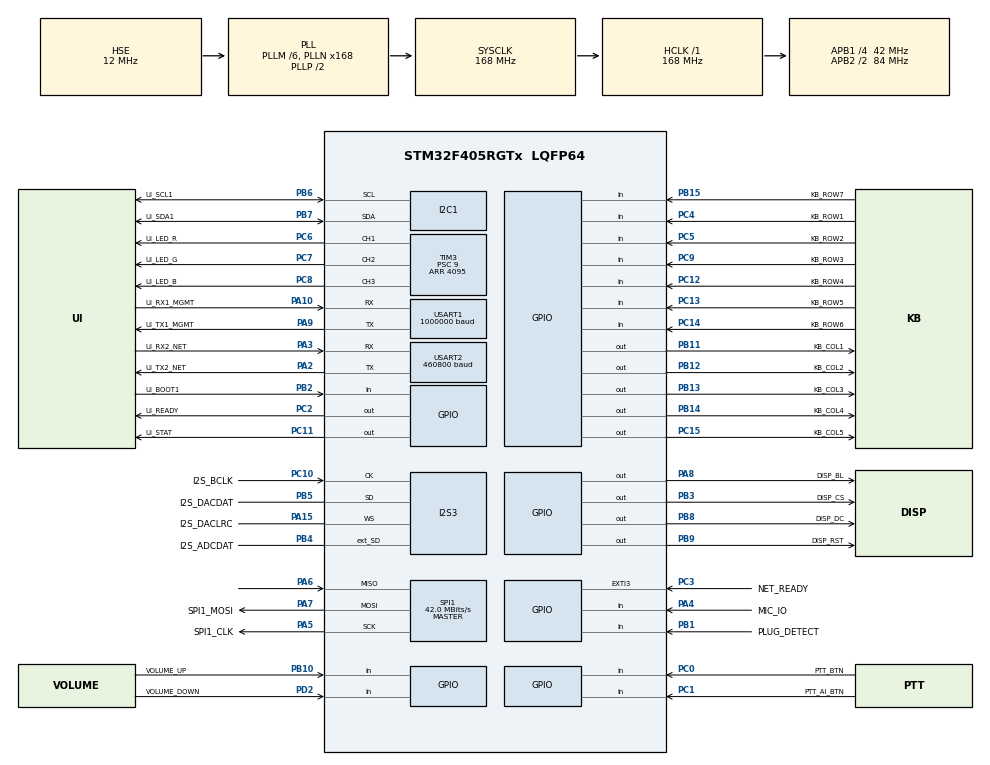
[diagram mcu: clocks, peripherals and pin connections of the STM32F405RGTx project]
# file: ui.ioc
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Dma.I2S3_EXT_RX.5.Direction=DMA_PERIPH_TO_MEMORY
Dma.I2S3_EXT_RX.5.FIFOMode=DMA_FIFOMODE_DISABLE
Dma.I2S3_EXT_RX.5.Instance=DMA1_Stream0
Dma.I2S3_EXT_RX.5.MemDataAlignment=DMA_MDATAALIGN_HALFWORD
Dma.I2S3_EXT_RX.5.MemInc=DMA_MINC_ENABLE
Dma.I2S3_EXT_RX.5.Mode=DMA_CIRCULAR
Dma.I2S3_EXT_RX.5.PeriphDataAlignment=DMA_PDATAALIGN_HALFWORD
Dma.I2S3_EXT_RX.5.PeriphInc=DMA_PINC_DISABLE
Dma.I2S3_EXT_RX.5.Priority=DMA_PRIORITY_HIGH
Dma.Request0=USART2_RX
Dma.Request1=USART2_TX
Dma.Request2=USART1_RX
Dma.Request3=USART1_TX
Dma.Request4=SPI3_TX
Dma.Request5=I2S3_EXT_RX
Dma.Request6=SPI1_RX
Dma.Request7=SPI1_TX
Dma.SPI1_RX.6.Direction=DMA_PERIPH_TO_MEMORY
Dma.SPI1_RX.6.FIFOMode=DMA_FIFOMODE_DISABLE
Dma.SPI1_RX.6.Instance=DMA2_Stream0
Dma.SPI1_RX.6.MemDataAlignment=DMA_MDATAALIGN_BYTE
Dma.SPI1_RX.6.MemInc=DMA_MINC_ENABLE
Dma.SPI1_RX.6.Mode=DMA_NORMAL
Dma.SPI1_RX.6.PeriphDataAlignment=DMA_PDATAALIGN_BYTE
Dma.SPI1_RX.6.PeriphInc=DMA_PINC_DISABLE
Dma.SPI1_RX.6.Priority=DMA_PRIORITY_LOW
Dma.SPI1_TX.7.Direction=DMA_MEMORY_TO_PERIPH
Dma.SPI1_TX.7.FIFOMode=DMA_FIFOMODE_DISABLE
Dma.SPI1_TX.7.Instance=DMA2_Stream3
Dma.SPI1_TX.7.MemDataAlignment=DMA_MDATAALIGN_BYTE
Dma.SPI1_TX.7.MemInc=DMA_MINC_ENABLE
Dma.SPI1_TX.7.Mode=DMA_NORMAL
Dma.SPI1_TX.7.PeriphDataAlignment=DMA_PDATAALIGN_BYTE
Dma.SPI1_TX.7.PeriphInc=DMA_PINC_DISABLE
Dma.SPI1_TX.7.Priority=DMA_PRIORITY_LOW
Dma.SPI3_TX.4.Direction=DMA_MEMORY_TO_PERIPH
Dma.SPI3_TX.4.FIFOMode=DMA_FIFOMODE_DISABLE
Dma.SPI3_TX.4.Instance=DMA1_Stream7
Dma.SPI3_TX.4.MemDataAlignment=DMA_MDATAALIGN_HALFWORD
Dma.SPI3_TX.4.MemInc=DMA_MINC_ENABLE
Dma.SPI3_TX.4.Mode=DMA_CIRCULAR
Dma.SPI3_TX.4.PeriphDataAlignment=DMA_PDATAALIGN_HALFWORD
Dma.SPI3_TX.4.PeriphInc=DMA_PINC_DISABLE
Dma.SPI3_TX.4.Priority=DMA_PRIORITY_HIGH
Dma.USART1_RX.2.Direction=DMA_PERIPH_TO_MEMORY
Dma.USART1_RX.2.FIFOMode=DMA_FIFOMODE_DISABLE
Dma.USART1_RX.2.Instance=DMA2_Stream5
Dma.USART1_RX.2.MemDataAlignment=DMA_MDATAALIGN_BYTE
Dma.USART1_RX.2.MemInc=DMA_MINC_ENABLE
Dma.USART1_RX.2.Mode=DMA_CIRCULAR
Dma.USART1_RX.2.PeriphDataAlignment=DMA_PDATAALIGN_BYTE
Dma.USART1_RX.2.PeriphInc=DMA_PINC_DISABLE
Dma.USART1_RX.2.Priority=DMA_PRIORITY_LOW
Dma.USART1_TX.3.Direction=DMA_MEMORY_TO_PERIPH
Dma.USART1_TX.3.FIFOMode=DMA_FIFOMODE_DISABLE
Dma.USART1_TX.3.Instance=DMA2_Stream7
Dma.USART1_TX.3.MemDataAlignment=DMA_MDATAALIGN_BYTE
Dma.USART1_TX.3.MemInc=DMA_MINC_ENABLE
Dma.USART1_TX.3.Mode=DMA_NORMAL
Dma.USART1_TX.3.PeriphDataAlignment=DMA_PDATAALIGN_BYTE
Dma.USART1_TX.3.PeriphInc=DMA_PINC_DISABLE
Dma.USART1_TX.3.Priority=DMA_PRIORITY_LOW
Dma.USART2_RX.0.Direction=DMA_PERIPH_TO_MEMORY
Dma.USART2_RX.0.FIFOMode=DMA_FIFOMODE_DISABLE
Dma.USART2_RX.0.Instance=DMA1_Stream5
Dma.USART2_RX.0.MemDataAlignment=DMA_MDATAALIGN_BYTE
Dma.USART2_RX.0.MemInc=DMA_MINC_ENABLE
Dma.USART2_RX.0.Mode=DMA_CIRCULAR
Dma.USART2_RX.0.PeriphDataAlignment=DMA_PDATAALIGN_BYTE
Dma.USART2_RX.0.PeriphInc=DMA_PINC_DISABLE
Dma.USART2_RX.0.Priority=DMA_PRIORITY_VERY_HIGH
Dma.USART2_TX.1.Direction=DMA_MEMORY_TO_PERIPH
Dma.USART2_TX.1.FIFOMode=DMA_FIFOMODE_DISABLE
Dma.USART2_TX.1.Instance=DMA1_Stream6
Dma.USART2_TX.1.MemDataAlignment=DMA_MDATAALIGN_BYTE
Dma.USART2_TX.1.MemInc=DMA_MINC_ENABLE
Dma.USART2_TX.1.Mode=DMA_NORMAL
Dma.USART2_TX.1.PeriphDataAlignment=DMA_PDATAALIGN_BYTE
Dma.USART2_TX.1.PeriphInc=DMA_PINC_DISABLE
Dma.USART2_TX.1.Priority=DMA_PRIORITY_VERY_HIGH
I2S3.AudioFreq=I2S_AUDIOFREQ_8K
I2S3.CPOL=I2S_CPOL_LOW
I2S3.DataFormat=I2S_DATAFORMAT_16B_EXTENDED
I2S3.ErrorAudioFreq=-0.36 %
I2S3.FullDuplexMode=I2S_FULLDUPLEXMODE_ENABLE
I2S3.Instance=SPI$Index
I2S3.RealAudioFreq=7.971 KHz
I2S3.Standard=I2S_STANDARD_MSB
I2S3.VirtualMode=I2S_MODE_SLAVE
Mcu.Family=STM32F4
Mcu.Name=STM32F405RGTx
Mcu.Package=LQFP64
NVIC.DMA1_Stream0_IRQn=true\:0\:0\:false\:false\:true\:false\:true\:true
NVIC.DMA1_Stream5_IRQn=true\:1\:0\:true\:false\:true\:false\:true\:true
NVIC.DMA1_Stream6_IRQn=true\:1\:0\:true\:false\:true\:false\:true\:true
NVIC.DMA1_Stream7_IRQn=true\:0\:0\:false\:false\:true\:false\:true\:true
NVIC.DMA2_Stream0_IRQn=true\:0\:0\:false\:false\:true\:false\:true\:true
NVIC.DMA2_Stream3_IRQn=true\:2\:0\:false\:false\:true\:false\:true\:true
NVIC.DMA2_Stream5_IRQn=true\:1\:0\:true\:false\:true\:false\:true\:true
NVIC.DMA2_Stream7_IRQn=true\:1\:0\:true\:false\:true\:false\:true\:true
NVIC.PriorityGroup=NVIC_PRIORITYGROUP_4
NVIC.RCC_IRQn=true\:0\:0\:false\:false\:true\:true\:false\:true
NVIC.SPI1_IRQn=true\:0\:0\:false\:false\:true\:true\:true\:true
NVIC.SPI3_IRQn=true\:0\:0\:false\:false\:true\:true\:true\:true
NVIC.TIM2_IRQn=true\:0\:0\:false\:false\:true\:true\:true\:true
NVIC.TIM3_IRQn=true\:0\:0\:false\:false\:true\:true\:true\:true
NVIC.TIM4_IRQn=true\:0\:0\:false\:false\:true\:true\:true\:true
NVIC.TIM5_IRQn=true\:0\:0\:false\:false\:true\:true\:true\:true
NVIC.TIM6_DAC_IRQn=true\:0\:0\:false\:false\:true\:true\:true\:true
NVIC.USART1_IRQn=true\:0\:0\:false\:false\:true\:true\:true\:true
NVIC.USART2_IRQn=true\:0\:0\:false\:false\:true\:true\:true\:true
PA10.GPIO_Label=UI_RX1_MGMT
PA10.Mode=Asynchronous
PA10.Signal=USART1_RX
PA13.Mode=Serial_Wire
PA13.Signal=SYS_JTMS-SWDIO
PA14.Mode=Serial_Wire
PA14.Signal=SYS_JTCK-SWCLK
PA15.GPIO_Label=I2S_DACLRC
PA15.Mode=Full_Duplex_Slave
PA15.Signal=I2S3_WS
PA2.GPIO_Label=UI_TX2_NET
PA2.Mode=Asynchronous
PA2.Signal=USART2_TX
PA3.GPIO_Label=UI_RX2_NET
PA3.GPIO_PuPd=GPIO_PULLDOWN
PA3.Mode=Asynchronous
PA3.Signal=USART2_RX
PA4.GPIO_Label=MIC_IO
PA4.Signal=GPIO_Input
PA5.GPIO_Label=SPI1_CLK
PA5.Mode=Full_Duplex_Master
PA5.Signal=SPI1_SCK
PA6.Mode=Full_Duplex_Master
PA6.Signal=SPI1_MISO
PA7.GPIO_Label=SPI1_MOSI
PA7.Mode=Full_Duplex_Master
PA7.Signal=SPI1_MOSI
PA8.GPIO_Label=DISP_BL
PA8.GPIO_PuPd=GPIO_NOPULL
PA8.Signal=GPIO_Output
PA9.GPIO_Label=UI_TX1_MGMT
PA9.Mode=Asynchronous
PA9.Signal=USART1_TX
PB1.GPIO_Label=PLUG_DETECT
PB1.Signal=GPIO_Input
PB10.GPIO_Label=VOLUME_UP
PB10.Signal=GPIO_Input
PB11.GPIO_Label=KB_COL1
PB11.Signal=GPIO_Output
PB12.GPIO_Label=KB_COL2
PB12.Signal=GPIO_Output
PB13.GPIO_Label=KB_COL3
PB13.Signal=GPIO_Output
PB14.GPIO_Label=KB_COL4
PB14.Signal=GPIO_Output
PB15.GPIO_Label=KB_ROW7
PB15.GPIO_PuPd=GPIO_PULLDOWN
PB15.Signal=GPIO_Input
PB2.GPIO_Label=UI_BOOT1
PB2.Signal=GPIO_Input
PB3.GPIO_Label=DISP_CS
PB3.Signal=GPIO_Output
PB4.GPIO_Label=I2S_ADCDAT
PB4.Mode=Full_Duplex_Slave
PB4.Signal=I2S3_ext_SD
PB5.GPIO_Label=I2S_DACDAT
PB5.Mode=Full_Duplex_Slave
PB5.Signal=I2S3_SD
PB6.GPIO_Label=UI_SCL1
PB6.Mode=I2C
PB6.Signal=I2C1_SCL
PB7.GPIO_Label=UI_SDA1
PB7.Mode=I2C
PB7.Signal=I2C1_SDA
PB8.GPIO_Label=DISP_DC
PB8.Signal=GPIO_Output
PB9.GPIO_Label=DISP_RST
PB9.Signal=GPIO_Output
PC0.GPIO_Label=PTT_BTN
PC0.GPIO_PuPd=GPIO_PULLUP
PC0.Signal=GPIO_Input
PC1.GPIO_Label=PTT_AI_BTN
PC1.GPIO_PuPd=GPIO_PULLUP
PC1.Signal=GPIO_Input
PC10.GPIO_Label=I2S_BCLK
PC10.Mode=Full_Duplex_Slave
PC10.Signal=I2S3_CK
PC11.GPIO_Label=UI_STAT
PC11.GPIO_PuPd=GPIO_PULLDOWN
PC11.GPIO_Speed=GPIO_SPEED_FREQ_MEDIUM
PC11.Signal=GPIO_Output
PC12.GPIO_Label=KB_ROW4
PC12.GPIO_PuPd=GPIO_PULLDOWN
PC12.Signal=GPIO_Input
PC13-ANTI_TAMP.GPIO_Label=KB_ROW5
PC13-ANTI_TAMP.GPIO_PuPd=GPIO_PULLDOWN
PC13-ANTI_TAMP.Signal=GPIO_Input
PC14-OSC32_IN.GPIO_Label=KB_ROW6
PC14-OSC32_IN.GPIO_PuPd=GPIO_PULLDOWN
PC14-OSC32_IN.Signal=GPIO_Input
PC15-OSC32_OUT.GPIO_Label=KB_COL5
PC15-OSC32_OUT.Signal=GPIO_Output
PC2.GPIO_Label=UI_READY
PC2.Signal=GPIO_Output
PC3.GPIO_Label=NET_READY
PC3.Signal=GPXTI3
PC4.GPIO_Label=KB_ROW1
PC4.GPIO_PuPd=GPIO_PULLDOWN
PC4.Signal=GPIO_Input
PC5.GPIO_Label=KB_ROW2
PC5.GPIO_PuPd=GPIO_PULLDOWN
PC5.Signal=GPIO_Input
PC6.GPIO_Label=UI_LED_R
PC6.Signal=S_TIM3_CH1
PC7.GPIO_Label=UI_LED_G
PC7.Signal=S_TIM3_CH2
PC8.GPIO_Label=UI_LED_B
PC8.Signal=S_TIM3_CH3
PC9.GPIO_Label=KB_ROW3
PC9.GPIO_PuPd=GPIO_PULLDOWN
PC9.Signal=GPIO_Input
PD2.GPIO_Label=VOLUME_DOWN
PD2.Signal=GPIO_Input
PH0-OSC_IN.GPIO_Label=MCLK
PH0-OSC_IN.Mode=HSE-External-Clock-Source
PH0-OSC_IN.Signal=RCC_OSC_IN
PH1-OSC_OUT.GPIO_Label=NC
PH1-OSC_OUT.Mode=HSE-External-Clock-Source
PH1-OSC_OUT.Signal=RCC_OSC_OUT
ProjectManager.HeapSize=0x200
ProjectManager.StackSize=0x400
ProjectManager.TargetToolchain=CMake
RCC.48MHZClocksFreq_Value=48000000
RCC.AHBFreq_Value=168000000
RCC.APB1CLKDivider=RCC_HCLK_DIV4
RCC.APB1Freq_Value=42000000
RCC.APB1TimFreq_Value=84000000
RCC.APB2CLKDivider=RCC_HCLK_DIV2
RCC.APB2Freq_Value=84000000
RCC.APB2TimFreq_Value=168000000
RCC.CortexFreq_Value=168000000
RCC.EXTERNAL_CLOCK_VALUE=2048000
RCC.HCLKFreq_Value=168000000
RCC.HSE_VALUE=12000000
RCC.HSI_VALUE=16000000
RCC.LSE_VALUE=32768
RCC.PLLI2SN=50
RCC.PLLM=6
RCC.PLLN=168
RCC.PLLQ=7
RCC.PLLSourceVirtual=RCC_PLLSOURCE_HSE
RCC.SYSCLKFreq_VALUE=168000000
RCC.SYSCLKSource=RCC_SYSCLKSOURCE_PLLCLK
RCC.VCOOutputFreq_Value=336000000
SH.S_TIM3_CH1.0=TIM3_CH1,PWM Generation1 CH1
SH.S_TIM3_CH2.0=TIM3_CH2,PWM Generation2 CH2
SH.S_TIM3_CH3.0=TIM3_CH3,PWM Generation3 CH3
SPI1.CalculateBaudRate=42.0 MBits/s
SPI1.Direction=SPI_DIRECTION_2LINES
SPI1.Mode=SPI_MODE_MASTER
SPI1.VirtualType=VM_MASTER
TIM2.Period=100
TIM2.Prescaler=839
TIM3.AutoReloadPreload=TIM_AUTORELOAD_PRELOAD_DISABLE
TIM3.Channel-PWM\ Generation1\ CH1=TIM_CHANNEL_1
TIM3.Channel-PWM\ Generation2\ CH2=TIM_CHANNEL_2
TIM3.Channel-PWM\ Generation3\ CH3=TIM_CHANNEL_3
TIM3.ClockDivision=TIM_CLOCKDIVISION_DIV1
TIM3.Period=4095
TIM3.Prescaler=9
TIM4.Period=4999
TIM4.Prescaler=8399
TIM5.Period=4999
TIM5.Prescaler=8399
TIM6.Period=99
TIM6.Prescaler=16799
TIM7.Period=199
TIM7.Prescaler=83
USART1.BaudRate=1000000
USART1.Parity=PARITY_EVEN
USART1.VirtualMode=VM_ASYNC
USART1.WordLength=WORDLENGTH_9B
USART2.BaudRate=460800
USART2.OverSampling=UART_OVERSAMPLING_16
USART2.Parity=PARITY_NONE
USART2.StopBits=STOPBITS_1
USART2.VirtualMode=VM_ASYNC
USART2.WordLength=WORDLENGTH_8B
VP_CRC_VS_CRC.Mode=CRC_Activate
VP_RNG_VS_RNG.Mode=RNG_Activate
VP_TIM2_VS_ClockSourceINT.Mode=Internal
VP_TIM3_VS_ClockSourceINT.Mode=Internal
VP_TIM4_VS_ClockSourceINT.Mode=Internal
VP_TIM5_VS_ClockSourceINT.Mode=Internal
VP_TIM6_VS_ClockSourceINT.Mode=Enable_Timer
VP_TIM7_VS_ClockSourceINT.Mode=Enable_Timer
VP_TIM7_VS_OPM.Mode=OPM_bit
board=custom

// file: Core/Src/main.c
/* USER CODE BEGIN Header */
/**
  ******************************************************************************
  * @file           : main.c
  * @brief          : Main program body
  ******************************************************************************
  * @attention
  *
  * Copyright (c) 2024 STMicroelectronics.
  * All rights reserved.
  *
  * This software is licensed under terms that can be found in the LICENSE file
  * in the root directory of this software component.
  * If no LICENSE file comes with this software, it is provided AS-IS.
  *
  ******************************************************************************
  */
/* USER CODE END Header */
#include "main.h"

/* USER CODE BEGIN Includes */
#include "app_main.hh"
/* USER CODE END Includes */

CRC_HandleTypeDef hcrc;

I2C_HandleTypeDef hi2c1;

I2S_HandleTypeDef hi2s3;
DMA_HandleTypeDef hdma_spi3_tx;
DMA_HandleTypeDef hdma_i2s3_ext_rx;

RNG_HandleTypeDef hrng;

SPI_HandleTypeDef hspi1;
DMA_HandleTypeDef hdma_spi1_rx;
DMA_HandleTypeDef hdma_spi1_tx;

TIM_HandleTypeDef htim2;
TIM_HandleTypeDef htim3;
TIM_HandleTypeDef htim4;
TIM_HandleTypeDef htim5;
TIM_HandleTypeDef htim6;
TIM_HandleTypeDef htim7;

UART_HandleTypeDef huart1;
UART_HandleTypeDef huart2;
DMA_HandleTypeDef hdma_usart1_rx;
DMA_HandleTypeDef hdma_usart1_tx;
DMA_HandleTypeDef hdma_usart2_rx;
DMA_HandleTypeDef hdma_usart2_tx;

void SystemClock_Config(void);
static void MX_GPIO_Init(void);
static void MX_DMA_Init(void);
static void MX_I2C1_Init(void);
static void MX_I2S3_Init(void);
static void MX_SPI1_Init(void);
static void MX_USART1_UART_Init(void);
static void MX_USART2_UART_Init(void);
static void MX_TIM2_Init(void);
static void MX_RNG_Init(void);
static void MX_CRC_Init(void);
static void MX_TIM3_Init(void);
static void MX_TIM4_Init(void);
static void MX_TIM5_Init(void);
static void MX_TIM6_Init(void);
static void MX_TIM7_Init(void);

int main(void)
{

  /* MCU Configuration--------------------------------------------------------*/

  /* Reset of all peripherals, Initializes the Flash interface and the Systick. */
  HAL_Init();

  /* Configure the system clock */
  SystemClock_Config();

  /* Initialize all configured peripherals */
  MX_GPIO_Init();
  MX_DMA_Init();
  MX_I2C1_Init();
  MX_I2S3_Init();
  MX_SPI1_Init();
  MX_USART1_UART_Init();
  MX_USART2_UART_Init();
  MX_TIM2_Init();
  MX_RNG_Init();
  MX_CRC_Init();
  MX_TIM3_Init();
  MX_TIM4_Init();
  MX_TIM5_Init();
  MX_TIM6_Init();
  MX_TIM7_Init();

  /* Infinite loop */
  /* USER CODE BEGIN WHILE */
  return app_main();
  while (1)
  {
    /* USER CODE END WHILE */

  }
}

void SystemClock_Config(void)
{
  RCC_OscInitTypeDef RCC_OscInitStruct = {0};
  RCC_ClkInitTypeDef RCC_ClkInitStruct = {0};

  /** Configure the main internal regulator output voltage
  */
  __HAL_RCC_PWR_CLK_ENABLE();
  __HAL_PWR_VOLTAGESCALING_CONFIG(PWR_REGULATOR_VOLTAGE_SCALE1);

  /** Initializes the RCC Oscillators according to the specified parameters
  * in the RCC_OscInitTypeDef structure.
  */
  RCC_OscInitStruct.OscillatorType = RCC_OSCILLATORTYPE_HSE;
  RCC_OscInitStruct.HSEState = RCC_HSE_BYPASS;
  RCC_OscInitStruct.PLL.PLLState = RCC_PLL_ON;
  RCC_OscInitStruct.PLL.PLLSource = RCC_PLLSOURCE_HSE;
  RCC_OscInitStruct.PLL.PLLM = 6;
  RCC_OscInitStruct.PLL.PLLN = 168;
  RCC_OscInitStruct.PLL.PLLP = RCC_PLLP_DIV2;
  RCC_OscInitStruct.PLL.PLLQ = 7;
  if (HAL_RCC_OscConfig(&RCC_OscInitStruct) != HAL_OK)
  {
    Error_Handler();
  }

  /** Initializes the CPU, AHB and APB buses clocks
  */
  RCC_ClkInitStruct.ClockType = RCC_CLOCKTYPE_HCLK|RCC_CLOCKTYPE_SYSCLK
                              |RCC_CLOCKTYPE_PCLK1|RCC_CLOCKTYPE_PCLK2;
  RCC_ClkInitStruct.SYSCLKSource = RCC_SYSCLKSOURCE_PLLCLK;
  RCC_ClkInitStruct.AHBCLKDivider = RCC_SYSCLK_DIV1;
  RCC_ClkInitStruct.APB1CLKDivider = RCC_HCLK_DIV4;
  RCC_ClkInitStruct.APB2CLKDivider = RCC_HCLK_DIV2;

  if (HAL_RCC_ClockConfig(&RCC_ClkInitStruct, FLASH_LATENCY_5) != HAL_OK)
  {
    Error_Handler();
  }
}

static void MX_CRC_Init(void)
{

  hcrc.Instance = CRC;
  if (HAL_CRC_Init(&hcrc) != HAL_OK)
  {
    Error_Handler();
  }

}

static void MX_I2C1_Init(void)
{

  hi2c1.Instance = I2C1;
  hi2c1.Init.ClockSpeed = 100000;
  hi2c1.Init.DutyCycle = I2C_DUTYCYCLE_2;
  hi2c1.Init.OwnAddress1 = 0;
  hi2c1.Init.AddressingMode = I2C_ADDRESSINGMODE_7BIT;
  hi2c1.Init.DualAddressMode = I2C_DUALADDRESS_DISABLE;
  hi2c1.Init.OwnAddress2 = 0;
  hi2c1.Init.GeneralCallMode = I2C_GENERALCALL_DISABLE;
  hi2c1.Init.NoStretchMode = I2C_NOSTRETCH_DISABLE;
  if (HAL_I2C_Init(&hi2c1) != HAL_OK)
  {
    Error_Handler();
  }

}

static void MX_I2S3_Init(void)
{

  hi2s3.Instance = SPI3;
  hi2s3.Init.Mode = I2S_MODE_SLAVE_TX;
  hi2s3.Init.Standard = I2S_STANDARD_MSB;
  hi2s3.Init.DataFormat = I2S_DATAFORMAT_16B_EXTENDED;
  hi2s3.Init.MCLKOutput = I2S_MCLKOUTPUT_DISABLE;
  hi2s3.Init.AudioFreq = I2S_AUDIOFREQ_8K;
  hi2s3.Init.CPOL = I2S_CPOL_LOW;
  hi2s3.Init.ClockSource = I2S_CLOCK_PLL;
  hi2s3.Init.FullDuplexMode = I2S_FULLDUPLEXMODE_ENABLE;
  if (HAL_I2S_Init(&hi2s3) != HAL_OK)
  {
    Error_Handler();
  }

}

static void MX_RNG_Init(void)
{

  hrng.Instance = RNG;
  if (HAL_RNG_Init(&hrng) != HAL_OK)
  {
    Error_Handler();
  }

}

static void MX_SPI1_Init(void)
{

  /* SPI1 parameter configuration*/
  hspi1.Instance = SPI1;
  hspi1.Init.Mode = SPI_MODE_MASTER;
  hspi1.Init.Direction = SPI_DIRECTION_2LINES;
  hspi1.Init.DataSize = SPI_DATASIZE_8BIT;
  hspi1.Init.CLKPolarity = SPI_POLARITY_LOW;
  hspi1.Init.CLKPhase = SPI_PHASE_1EDGE;
  hspi1.Init.NSS = SPI_NSS_SOFT;
  hspi1.Init.BaudRatePrescaler = SPI_BAUDRATEPRESCALER_2;
  hspi1.Init.FirstBit = SPI_FIRSTBIT_MSB;
  hspi1.Init.TIMode = SPI_TIMODE_DISABLE;
  hspi1.Init.CRCCalculation = SPI_CRCCALCULATION_DISABLE;
  hspi1.Init.CRCPolynomial = 10;
  if (HAL_SPI_Init(&hspi1) != HAL_OK)
  {
    Error_Handler();
  }

}

static void MX_TIM2_Init(void)
{

  TIM_ClockConfigTypeDef sClockSourceConfig = {0};
  TIM_MasterConfigTypeDef sMasterConfig = {0};

  htim2.Instance = TIM2;
  htim2.Init.Prescaler = 839;
  htim2.Init.CounterMode = TIM_COUNTERMODE_UP;
  htim2.Init.Period = 100;
  htim2.Init.ClockDivision = TIM_CLOCKDIVISION_DIV1;
  htim2.Init.AutoReloadPreload = TIM_AUTORELOAD_PRELOAD_DISABLE;
  if (HAL_TIM_Base_Init(&htim2) != HAL_OK)
  {
    Error_Handler();
  }
  sClockSourceConfig.ClockSource = TIM_CLOCKSOURCE_INTERNAL;
  if (HAL_TIM_ConfigClockSource(&htim2, &sClockSourceConfig) != HAL_OK)
  {
    Error_Handler();
  }
  sMasterConfig.MasterOutputTrigger = TIM_TRGO_RESET;
  sMasterConfig.MasterSlaveMode = TIM_MASTERSLAVEMODE_DISABLE;
  if (HAL_TIMEx_MasterConfigSynchronization(&htim2, &sMasterConfig) != HAL_OK)
  {
    Error_Handler();
  }

}

static void MX_TIM3_Init(void)
{

  TIM_ClockConfigTypeDef sClockSourceConfig = {0};
  TIM_MasterConfigTypeDef sMasterConfig = {0};
  TIM_OC_InitTypeDef sConfigOC = {0};

  htim3.Instance = TIM3;
  htim3.Init.Prescaler = 9;
  htim3.Init.CounterMode = TIM_COUNTERMODE_UP;
  htim3.Init.Period = 4095;
  htim3.Init.ClockDivision = TIM_CLOCKDIVISION_DIV1;
  htim3.Init.AutoReloadPreload = TIM_AUTORELOAD_PRELOAD_DISABLE;
  if (HAL_TIM_Base_Init(&htim3) != HAL_OK)
  {
    Error_Handler();
  }
  sClockSourceConfig.ClockSource = TIM_CLOCKSOURCE_INTERNAL;
  if (HAL_TIM_ConfigClockSource(&htim3, &sClockSourceConfig) != HAL_OK)
  {
    Error_Handler();
  }
  if (HAL_TIM_PWM_Init(&htim3) != HAL_OK)
  {
    Error_Handler();
  }
  sMasterConfig.MasterOutputTrigger = TIM_TRGO_RESET;
  sMasterConfig.MasterSlaveMode = TIM_MASTERSLAVEMODE_DISABLE;
  if (HAL_TIMEx_MasterConfigSynchronization(&htim3, &sMasterConfig) != HAL_OK)
  {
    Error_Handler();
  }
  sConfigOC.OCMode = TIM_OCMODE_PWM1;
  sConfigOC.Pulse = 0;
  sConfigOC.OCPolarity = TIM_OCPOLARITY_HIGH;
  sConfigOC.OCFastMode = TIM_OCFAST_DISABLE;
  if (HAL_TIM_PWM_ConfigChannel(&htim3, &sConfigOC, TIM_CHANNEL_1) != HAL_OK)
  {
    Error_Handler();
  }
  if (HAL_TIM_PWM_ConfigChannel(&htim3, &sConfigOC, TIM_CHANNEL_2) != HAL_OK)
  {
    Error_Handler();
  }
  if (HAL_TIM_PWM_ConfigChannel(&htim3, &sConfigOC, TIM_CHANNEL_3) != HAL_OK)
  {
    Error_Handler();
  }
  HAL_TIM_MspPostInit(&htim3);

}

static void MX_TIM4_Init(void)
{

  TIM_ClockConfigTypeDef sClockSourceConfig = {0};
  TIM_MasterConfigTypeDef sMasterConfig = {0};

  htim4.Instance = TIM4;
  htim4.Init.Prescaler = 8399;
  htim4.Init.CounterMode = TIM_COUNTERMODE_UP;
  htim4.Init.Period = 4999;
  htim4.Init.ClockDivision = TIM_CLOCKDIVISION_DIV1;
  htim4.Init.AutoReloadPreload = TIM_AUTORELOAD_PRELOAD_DISABLE;
  if (HAL_TIM_Base_Init(&htim4) != HAL_OK)
  {
    Error_Handler();
  }
  sClockSourceConfig.ClockSource = TIM_CLOCKSOURCE_INTERNAL;
  if (HAL_TIM_ConfigClockSource(&htim4, &sClockSourceConfig) != HAL_OK)
  {
    Error_Handler();
  }
  sMasterConfig.MasterOutputTrigger = TIM_TRGO_RESET;
  sMasterConfig.MasterSlaveMode = TIM_MASTERSLAVEMODE_DISABLE;
  if (HAL_TIMEx_MasterConfigSynchronization(&htim4, &sMasterConfig) != HAL_OK)
  {
    Error_Handler();
  }

}

static void MX_TIM5_Init(void)
{

  TIM_ClockConfigTypeDef sClockSourceConfig = {0};
  TIM_MasterConfigTypeDef sMasterConfig = {0};

  htim5.Instance = TIM5;
  htim5.Init.Prescaler = 8399;
  htim5.Init.CounterMode = TIM_COUNTERMODE_UP;
  htim5.Init.Period = 4999;
  htim5.Init.ClockDivision = TIM_CLOCKDIVISION_DIV1;
  htim5.Init.AutoReloadPreload = TIM_AUTORELOAD_PRELOAD_DISABLE;
  if (HAL_TIM_Base_Init(&htim5) != HAL_OK)
  {
    Error_Handler();
  }
  sClockSourceConfig.ClockSource = TIM_CLOCKSOURCE_INTERNAL;
  if (HAL_TIM_ConfigClockSource(&htim5, &sClockSourceConfig) != HAL_OK)
  {
    Error_Handler();
  }
  sMasterConfig.MasterOutputTrigger = TIM_TRGO_RESET;
  sMasterConfig.MasterSlaveMode = TIM_MASTERSLAVEMODE_DISABLE;
  if (HAL_TIMEx_MasterConfigSynchronization(&htim5, &sMasterConfig) != HAL_OK)
  {
    Error_Handler();
  }

}

static void MX_TIM6_Init(void)
{

  TIM_MasterConfigTypeDef sMasterConfig = {0};

  htim6.Instance = TIM6;
  htim6.Init.Prescaler = 16799;
  htim6.Init.CounterMode = TIM_COUNTERMODE_UP;
  htim6.Init.Period = 99;
  htim6.Init.AutoReloadPreload = TIM_AUTORELOAD_PRELOAD_DISABLE;
  if (HAL_TIM_Base_Init(&htim6) != HAL_OK)
  {
    Error_Handler();
  }
  sMasterConfig.MasterOutputTrigger = TIM_TRGO_RESET;
  sMasterConfig.MasterSlaveMode = TIM_MASTERSLAVEMODE_DISABLE;
  if (HAL_TIMEx_MasterConfigSynchronization(&htim6, &sMasterConfig) != HAL_OK)
  {
    Error_Handler();
  }

}

static void MX_TIM7_Init(void)
{

  TIM_MasterConfigTypeDef sMasterConfig = {0};

  htim7.Instance = TIM7;
  htim7.Init.Prescaler = 83;
  htim7.Init.CounterMode = TIM_COUNTERMODE_UP;
  htim7.Init.Period = 199;
  htim7.Init.AutoReloadPreload = TIM_AUTORELOAD_PRELOAD_DISABLE;
  if (HAL_TIM_Base_Init(&htim7) != HAL_OK)
  {
    Error_Handler();
  }
  if (HAL_TIM_OnePulse_Init(&htim7, TIM_OPMODE_SINGLE) != HAL_OK)
  {
    Error_Handler();
  }
  sMasterConfig.MasterOutputTrigger = TIM_TRGO_RESET;
  sMasterConfig.MasterSlaveMode = TIM_MASTERSLAVEMODE_DISABLE;
  if (HAL_TIMEx_MasterConfigSynchronization(&htim7, &sMasterConfig) != HAL_OK)
  {
    Error_Handler();
  }

}

static void MX_USART1_UART_Init(void)
{

  huart1.Instance = USART1;
  huart1.Init.BaudRate = 1000000;
  huart1.Init.WordLength = UART_WORDLENGTH_9B;
  huart1.Init.StopBits = UART_STOPBITS_1;
  huart1.Init.Parity = UART_PARITY_EVEN;
  huart1.Init.Mode = UART_MODE_TX_RX;
  huart1.Init.HwFlowCtl = UART_HWCONTROL_NONE;
  huart1.Init.OverSampling = UART_OVERSAMPLING_16;
  if (HAL_UART_Init(&huart1) != HAL_OK)
  {
    Error_Handler();
  }

}

static void MX_USART2_UART_Init(void)
{

  huart2.Instance = USART2;
  huart2.Init.BaudRate = 460800;
  huart2.Init.WordLength = UART_WORDLENGTH_8B;
  huart2.Init.StopBits = UART_STOPBITS_1;
  huart2.Init.Parity = UART_PARITY_NONE;
  huart2.Init.Mode = UART_MODE_TX_RX;
  huart2.Init.HwFlowCtl = UART_HWCONTROL_NONE;
  huart2.Init.OverSampling = UART_OVERSAMPLING_16;
  if (HAL_UART_Init(&huart2) != HAL_OK)
  {
    Error_Handler();
  }

}

static void MX_DMA_Init(void)
{

  /* DMA controller clock enable */
  __HAL_RCC_DMA1_CLK_ENABLE();
  __HAL_RCC_DMA2_CLK_ENABLE();

  /* DMA interrupt init */
  /* DMA1_Stream0_IRQn interrupt configuration */
  HAL_NVIC_SetPriority(DMA1_Stream0_IRQn, 0, 0);
  HAL_NVIC_EnableIRQ(DMA1_Stream0_IRQn);
  /* DMA1_Stream5_IRQn interrupt configuration */
  HAL_NVIC_SetPriority(DMA1_Stream5_IRQn, 1, 0);
  HAL_NVIC_EnableIRQ(DMA1_Stream5_IRQn);
  /* DMA1_Stream6_IRQn interrupt configuration */
  HAL_NVIC_SetPriority(DMA1_Stream6_IRQn, 1, 0);
  HAL_NVIC_EnableIRQ(DMA1_Stream6_IRQn);
  /* DMA1_Stream7_IRQn interrupt configuration */
  HAL_NVIC_SetPriority(DMA1_Stream7_IRQn, 0, 0);
  HAL_NVIC_EnableIRQ(DMA1_Stream7_IRQn);
  /* DMA2_Stream0_IRQn interrupt configuration */
  HAL_NVIC_SetPriority(DMA2_Stream0_IRQn, 0, 0);
  HAL_NVIC_EnableIRQ(DMA2_Stream0_IRQn);
  /* DMA2_Stream3_IRQn interrupt configuration */
  HAL_NVIC_SetPriority(DMA2_Stream3_IRQn, 2, 0);
  HAL_NVIC_EnableIRQ(DMA2_Stream3_IRQn);
  /* DMA2_Stream5_IRQn interrupt configuration */
  HAL_NVIC_SetPriority(DMA2_Stream5_IRQn, 1, 0);
  HAL_NVIC_EnableIRQ(DMA2_Stream5_IRQn);
  /* DMA2_Stream7_IRQn interrupt configuration */
  HAL_NVIC_SetPriority(DMA2_Stream7_IRQn, 1, 0);
  HAL_NVIC_EnableIRQ(DMA2_Stream7_IRQn);

}

static void MX_GPIO_Init(void)
{
  GPIO_InitTypeDef GPIO_InitStruct = {0};

  /* GPIO Ports Clock Enable */
  __HAL_RCC_GPIOC_CLK_ENABLE();
  __HAL_RCC_GPIOH_CLK_ENABLE();
  __HAL_RCC_GPIOA_CLK_ENABLE();
  __HAL_RCC_GPIOB_CLK_ENABLE();
  __HAL_RCC_GPIOD_CLK_ENABLE();

  /*Configure GPIO pin Output Level */
  HAL_GPIO_WritePin(GPIOC, KB_COL5_Pin|UI_READY_Pin|UI_STAT_Pin, GPIO_PIN_RESET);

  /*Configure GPIO pin Output Level */
  HAL_GPIO_WritePin(GPIOB, KB_COL1_Pin|KB_COL2_Pin|KB_COL3_Pin|KB_COL4_Pin
                          |DISP_CS_Pin|DISP_DC_Pin|DISP_RST_Pin, GPIO_PIN_RESET);

  /*Configure GPIO pin Output Level */
  HAL_GPIO_WritePin(DISP_BL_GPIO_Port, DISP_BL_Pin, GPIO_PIN_RESET);

  /*Configure GPIO pins : KB_ROW5_Pin KB_ROW6_Pin KB_ROW1_Pin KB_ROW2_Pin
                           KB_ROW3_Pin KB_ROW4_Pin */
  GPIO_InitStruct.Pin = KB_ROW5_Pin|KB_ROW6_Pin|KB_ROW1_Pin|KB_ROW2_Pin
                          |KB_ROW3_Pin|KB_ROW4_Pin;
  GPIO_InitStruct.Mode = GPIO_MODE_INPUT;
  GPIO_InitStruct.Pull = GPIO_PULLDOWN;
  HAL_GPIO_Init(GPIOC, &GPIO_InitStruct);

  /*Configure GPIO pins : KB_COL5_Pin UI_READY_Pin */
  GPIO_InitStruct.Pin = KB_COL5_Pin|UI_READY_Pin;
  GPIO_InitStruct.Mode = GPIO_MODE_OUTPUT_PP;
  GPIO_InitStruct.Pull = GPIO_NOPULL;
  GPIO_InitStruct.Speed = GPIO_SPEED_FREQ_LOW;
  HAL_GPIO_Init(GPIOC, &GPIO_InitStruct);

  /*Configure GPIO pins : PTT_BTN_Pin PTT_AI_BTN_Pin */
  GPIO_InitStruct.Pin = PTT_BTN_Pin|PTT_AI_BTN_Pin;
  GPIO_InitStruct.Mode = GPIO_MODE_INPUT;
  GPIO_InitStruct.Pull = GPIO_PULLUP;
  HAL_GPIO_Init(GPIOC, &GPIO_InitStruct);

  /*Configure GPIO pin : NET_READY_Pin */
  GPIO_InitStruct.Pin = NET_READY_Pin;
  GPIO_InitStruct.Mode = GPIO_MODE_IT_RISING;
  GPIO_InitStruct.Pull = GPIO_NOPULL;
  HAL_GPIO_Init(NET_READY_GPIO_Port, &GPIO_InitStruct);

  /*Configure GPIO pin : MIC_IO_Pin */
  GPIO_InitStruct.Pin = MIC_IO_Pin;
  GPIO_InitStruct.Mode = GPIO_MODE_INPUT;
  GPIO_InitStruct.Pull = GPIO_NOPULL;
  HAL_GPIO_Init(MIC_IO_GPIO_Port, &GPIO_InitStruct);

  /*Configure GPIO pins : PLUG_DETECT_Pin UI_BOOT1_Pin VOLUME_UP_Pin */
  GPIO_InitStruct.Pin = PLUG_DETECT_Pin|UI_BOOT1_Pin|VOLUME_UP_Pin;
  GPIO_InitStruct.Mode = GPIO_MODE_INPUT;
  GPIO_InitStruct.Pull = GPIO_NOPULL;
  HAL_GPIO_Init(GPIOB, &GPIO_InitStruct);

  /*Configure GPIO pins : KB_COL1_Pin KB_COL2_Pin KB_COL3_Pin KB_COL4_Pin
                           DISP_CS_Pin DISP_DC_Pin DISP_RST_Pin */
  GPIO_InitStruct.Pin = KB_COL1_Pin|KB_COL2_Pin|KB_COL3_Pin|KB_COL4_Pin
                          |DISP_CS_Pin|DISP_DC_Pin|DISP_RST_Pin;
  GPIO_InitStruct.Mode = GPIO_MODE_OUTPUT_PP;
  GPIO_InitStruct.Pull = GPIO_NOPULL;
  GPIO_InitStruct.Speed = GPIO_SPEED_FREQ_LOW;
  HAL_GPIO_Init(GPIOB, &GPIO_InitStruct);

  /*Configure GPIO pin : KB_ROW7_Pin */
  GPIO_InitStruct.Pin = KB_ROW7_Pin;
  GPIO_InitStruct.Mode = GPIO_MODE_INPUT;
  GPIO_InitStruct.Pull = GPIO_PULLDOWN;
  HAL_GPIO_Init(KB_ROW7_GPIO_Port, &GPIO_InitStruct);

  /*Configure GPIO pin : DISP_BL_Pin */
  GPIO_InitStruct.Pin = DISP_BL_Pin;
  GPIO_InitStruct.Mode = GPIO_MODE_OUTPUT_PP;
  GPIO_InitStruct.Pull = GPIO_NOPULL;
  GPIO_InitStruct.Speed = GPIO_SPEED_FREQ_LOW;
  HAL_GPIO_Init(DISP_BL_GPIO_Port, &GPIO_InitStruct);

  /*Configure GPIO pin : UI_STAT_Pin */
  GPIO_InitStruct.Pin = UI_STAT_Pin;
  GPIO_InitStruct.Mode = GPIO_MODE_OUTPUT_PP;
  GPIO_InitStruct.Pull = GPIO_PULLDOWN;
  GPIO_InitStruct.Speed = GPIO_SPEED_FREQ_MEDIUM;
  HAL_GPIO_Init(UI_STAT_GPIO_Port, &GPIO_InitStruct);

  /*Configure GPIO pin : VOLUME_DOWN_Pin */
  GPIO_InitStruct.Pin = VOLUME_DOWN_Pin;
  GPIO_InitStruct.Mode = GPIO_MODE_INPUT;
  GPIO_InitStruct.Pull = GPIO_NOPULL;
  HAL_GPIO_Init(VOLUME_DOWN_GPIO_Port, &GPIO_InitStruct);

}

void Error_Handler(void)
{
  /* USER CODE BEGIN Error_Handler_Debug */
  /* User can add his own implementation to report the HAL error return state */
  __disable_irq();
  while (1)
  {
    HAL_GPIO_TogglePin(UI_LED_R_GPIO_Port, UI_LED_R_Pin);
    HAL_GPIO_TogglePin(UI_LED_G_GPIO_Port, UI_LED_G_Pin);
    HAL_GPIO_TogglePin(UI_LED_B_GPIO_Port, UI_LED_B_Pin);
    for (int i =0; i < 0x8FFFFF; ++i)
    {
      __NOP();
    }

  }
  /* USER CODE END Error_Handler_Debug */
}
